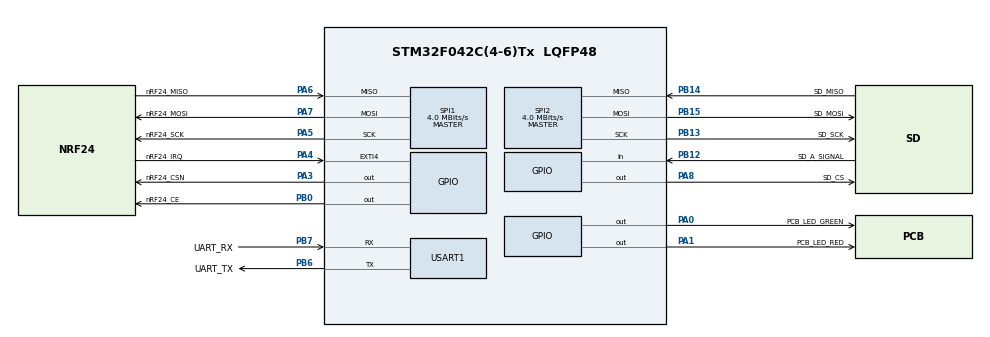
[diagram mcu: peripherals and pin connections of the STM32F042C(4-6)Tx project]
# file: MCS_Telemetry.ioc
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Mcu.Family=STM32F0
Mcu.Name=STM32F042C(4-6)Tx
Mcu.Package=LQFP48
PA0.GPIO_Label=PCB_LED_GREEN
PA0.Signal=GPIO_Output
PA1.GPIO_Label=PCB_LED_RED
PA1.Signal=GPIO_Output
PA13.GPIO_Label=SWDIO
PA13.Mode=Serial_Wire
PA13.Signal=SYS_SWDIO
PA14.GPIO_Label=SWCLK
PA14.Mode=Serial_Wire
PA14.Signal=SYS_SWCLK
PA3.GPIO_Label=nRF24_CSN
PA3.Signal=GPIO_Output
PA4.GPIO_Label=nRF24_IRQ
PA4.Signal=GPXTI4
PA5.GPIO_Label=nRF24_SCK
PA5.Mode=Full_Duplex_Master
PA5.Signal=SPI1_SCK
PA6.GPIO_Label=nRF24_MISO
PA6.Mode=Full_Duplex_Master
PA6.Signal=SPI1_MISO
PA7.GPIO_Label=nRF24_MOSI
PA7.Mode=Full_Duplex_Master
PA7.Signal=SPI1_MOSI
PA8.GPIO_Label=SD_CS
PA8.Signal=GPIO_Output
PB0.GPIO_Label=nRF24_CE
PB0.Signal=GPIO_Output
PB12.GPIO_Label=SD_A_SIGNAL
PB12.Signal=GPIO_Input
PB13.GPIO_Label=SD_SCK
PB13.Mode=Full_Duplex_Master
PB13.Signal=SPI2_SCK
PB14.GPIO_Label=SD_MISO
PB14.Mode=Full_Duplex_Master
PB14.Signal=SPI2_MISO
PB15.GPIO_Label=SD_MOSI
PB15.Mode=Full_Duplex_Master
PB15.Signal=SPI2_MOSI
PB6.GPIO_Label=UART_TX
PB6.Mode=Asynchronous
PB6.Signal=USART1_TX
PB7.GPIO_Label=UART_RX
PB7.Mode=Asynchronous
PB7.Signal=USART1_RX
PF0-OSC_IN.GPIO_Label=OSC_IN
PF0-OSC_IN.Mode=HSE-External-Oscillator
PF0-OSC_IN.Signal=RCC_OSC_IN
PF1-OSC_OUT.GPIO_Label=OSC_OUT
PF1-OSC_OUT.Mode=HSE-External-Oscillator
PF1-OSC_OUT.Signal=RCC_OSC_OUT
ProjectManager.HeapSize=0x200
ProjectManager.StackSize=0x400
ProjectManager.TargetToolchain=STM32CubeIDE
RCC.HSE_VALUE=16000000
RCC.PLLSourceVirtual=RCC_PLLSOURCE_HSE
SPI1.BaudRatePrescaler=SPI_BAUDRATEPRESCALER_2
SPI1.CalculateBaudRate=4.0 MBits/s
SPI1.DataSize=SPI_DATASIZE_8BIT
SPI1.Direction=SPI_DIRECTION_2LINES
SPI1.Mode=SPI_MODE_MASTER
SPI1.VirtualType=VM_MASTER
SPI2.CalculateBaudRate=4.0 MBits/s
SPI2.DataSize=SPI_DATASIZE_8BIT
SPI2.Direction=SPI_DIRECTION_2LINES
SPI2.Mode=SPI_MODE_MASTER
SPI2.VirtualType=VM_MASTER
USART1.VirtualMode-Asynchronous=VM_ASYNC
VP_FATFS_VS_Generic.Mode=User_defined
board=custom

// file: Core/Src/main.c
/* USER CODE BEGIN Header */
/**
  ******************************************************************************
  * @file           : main.c
  * @brief          : Main program body
  ******************************************************************************
  * @attention
  *
  * Copyright (c) 2023 STMicroelectronics.
  * All rights reserved.
  *
  * This software is licensed under terms that can be found in the LICENSE file
  * in the root directory of this software component.
  * If no LICENSE file comes with this software, it is provided AS-IS.
  *
  ******************************************************************************
  */
/* USER CODE END Header */
#include "main.h"
#include "fatfs.h"
#include "spi.h"
#include "usart.h"
#include "gpio.h"

/* USER CODE BEGIN Includes */
#include <stdio.h>
#include <SD_Card.h>
#include "nRF24L01/nRF24L01.h"
#include "nRF24L01/nRF24L01_Defs.h"
/* USER CODE END Includes */

/* USER CODE BEGIN PV */
volatile uint8_t nrf24_rx_flag, nrf24_tx_flag, nrf24_mr_flag;
uint8_t Nrf24_Message[NRF24_PAYLOAD_SIZE];
uint8_t Message[32];
uint8_t MessageLength;
uint8_t TxAddr[] = {0xEE, 0xDD, 0xCC, 0xBB, 0xAA};
uint8_t RxAddr[] = {0xEE, 0xDD, 0xCC, 0xBB, 0xAA};
/* USER CODE END PV */

void SystemClock_Config(void);

int main(void)
{

  /* MCU Configuration--------------------------------------------------------*/

  /* Reset of all peripherals, Initializes the Flash interface and the Systick. */
  HAL_Init();

  /* Configure the system clock */
  SystemClock_Config();

  /* Initialize all configured peripherals */
  MX_GPIO_Init();
  MX_SPI1_Init();
  MX_SPI2_Init();
  MX_USART1_UART_Init();
  MX_FATFS_Init();
  /* USER CODE BEGIN 2 */
  nRF24_Init(&hspi1);
  nRF24_SetRXAddress(0, RxAddr);
  nRF24_SetTXAddress(TxAddr);
  nRF24_RX_Mode();

  /* USER CODE END 2 */

  /* Infinite loop */
  while (1)
  {

  }
}

void SystemClock_Config(void)
{
  RCC_OscInitTypeDef RCC_OscInitStruct = {0};
  RCC_ClkInitTypeDef RCC_ClkInitStruct = {0};
  RCC_PeriphCLKInitTypeDef PeriphClkInit = {0};

  /** Initializes the RCC Oscillators according to the specified parameters
  * in the RCC_OscInitTypeDef structure.
  */
  RCC_OscInitStruct.OscillatorType = RCC_OSCILLATORTYPE_HSI;
  RCC_OscInitStruct.HSIState = RCC_HSI_ON;
  RCC_OscInitStruct.HSICalibrationValue = RCC_HSICALIBRATION_DEFAULT;
  RCC_OscInitStruct.PLL.PLLState = RCC_PLL_NONE;
  if (HAL_RCC_OscConfig(&RCC_OscInitStruct) != HAL_OK)
  {
    Error_Handler();
  }

  /** Initializes the CPU, AHB and APB buses clocks
  */
  RCC_ClkInitStruct.ClockType = RCC_CLOCKTYPE_HCLK|RCC_CLOCKTYPE_SYSCLK
                              |RCC_CLOCKTYPE_PCLK1;
  RCC_ClkInitStruct.SYSCLKSource = RCC_SYSCLKSOURCE_HSI;
  RCC_ClkInitStruct.AHBCLKDivider = RCC_SYSCLK_DIV1;
  RCC_ClkInitStruct.APB1CLKDivider = RCC_HCLK_DIV1;

  if (HAL_RCC_ClockConfig(&RCC_ClkInitStruct, FLASH_LATENCY_0) != HAL_OK)
  {
    Error_Handler();
  }
  PeriphClkInit.PeriphClockSelection = RCC_PERIPHCLK_USART1;
  PeriphClkInit.Usart1ClockSelection = RCC_USART1CLKSOURCE_PCLK1;
  if (HAL_RCCEx_PeriphCLKConfig(&PeriphClkInit) != HAL_OK)
  {
    Error_Handler();
  }
}

void Error_Handler(void)
{
  __disable_irq();
  while (1)
  {
  }
}
